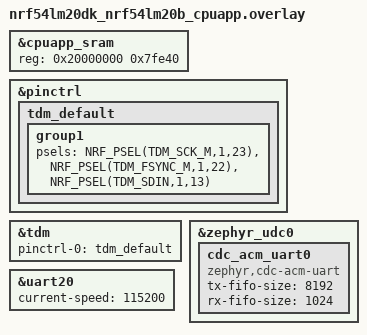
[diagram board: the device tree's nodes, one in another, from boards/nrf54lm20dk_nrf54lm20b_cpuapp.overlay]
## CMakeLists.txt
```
cmake_minimum_required(VERSION 3.20.0)

find_package(Zephyr REQUIRED HINTS $ENV{ZEPHYR_BASE})
project(16_3mic_eval)

target_sources(app PRIVATE
  src/main.c
  src/eval_config.c
  src/audio_capture_adapter.c
  src/beamformer_delay_sum.c
  src/telemetry_protocol.c
  src/telemetry_transport.c
  src/run_controller.c
  src/command_interface.c
)

target_include_directories(app PRIVATE src)
```

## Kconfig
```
#
# 3-microphone beamforming evaluation firmware
#

source "Kconfig.zephyr"

menu "3-mic TDM capture"

config EVAL_TDM_SLOTS
	int "TDM slots per frame"
	range 4 8
	default 4
	help
	  Number of 32-bit slots in each TDM frame. Three mics plus one unused
	  slot by default, giving SCK = 16 kHz * 32 * 4 = 2.048 MHz. Raise to 8
	  if the mic needs a longer frame or a faster SCK.

config EVAL_SLOT_LEFT
	int "TDM slot of the left mic"
	range 0 7
	default 0
	help
	  Slot order follows the WS -> WSO daisy chain. The mic whose WS is
	  driven by the nRF FSYNC pin is slot 0.

config EVAL_SLOT_CENTER
	int "TDM slot of the center mic"
	range 0 7
	default 1

config EVAL_SLOT_RIGHT
	int "TDM slot of the right mic"
	range 0 7
	default 2

config EVAL_SLOT_BIT_OFFSET
	int "Bit offset of the sample inside its TDM slot"
	range 0 1
	default 0
	help
	  The nRF TDM driver samples PCM_SHORT frames with no channel delay. If
	  a logic analyzer shows the mic starting its MSB one SCK after the
	  frame-sync edge, set this to 1.

config EVAL_CAPTURE_GAIN_SHIFT
	int "Extra digital gain from the mic's 24-bit domain, 6 dB per step"
	range 0 4
	default 0

config EVAL_FRAME_QUEUE_DEPTH
	int "Frames buffered between the capture thread and the evaluation thread"
	range 2 32
	default 8
	help
	  Each entry is one 16 ms three-channel frame (1.5 KB). If the
	  evaluation thread falls behind, capture never blocks: the frame is
	  dropped and counted.

endmenu

menu "Beamformer and run defaults"

config EVAL_DEFAULT_DURATION_S
	int "Default run duration (s), 0 = until 'stop'"
	default 20

config EVAL_MAX_DELAY_SAMPLES
	int "Longest beamformer delay supported, in samples"
	range 1 127
	default 64
	help
	  At 16 kHz one sample is 62.5 us, or about 2.1 cm of path length.

config EVAL_BF_LEFT_DELAY
	int "Default left-mic delay (samples)"
	default 0

config EVAL_BF_CENTER_DELAY
	int "Default center-mic delay (samples)"
	default 0

config EVAL_BF_RIGHT_DELAY
	int "Default right-mic delay (samples)"
	default 0

config EVAL_BF_GAIN_Q15
	int "Default per-mic beamformer weight, Q15 (32767 = 1.0)"
	range 0 32767
	default 32767

config EVAL_TX_RING_BYTES
	int "Telemetry transmit ring buffer (bytes)"
	default 65536
	help
	  Audio and telemetry packets are staged here and drained into the USB
	  CDC ACM FIFO. Four 16-bit streams are 128 kB/s, so 64 KiB is about
	  half a second of slack. When full, audio chunks are dropped and the
	  host records a gap.

config EVAL_STATUS_PERIOD_MS
	int "AUDIO_STATS emission period during a run (ms)"
	default 1000

config EVAL_TEXT_MODE_AT_BOOT
	bool "Start in human-readable text mode (binary framing enabled by the host tool)"
	default y

endmenu
```

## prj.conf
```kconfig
# --- Audio capture (TDM, three ICS-52000 microphones) ---
CONFIG_I2S=y

# --- Telemetry link: USB high-speed, CDC ACM. The stack initialises and
#     enables itself at boot; the class exposes the interrupt-driven UART API
#     that telemetry_transport.c drains its ring through. ---
CONFIG_USB_DEVICE_STACK_NEXT=y
CONFIG_USBD_CDC_ACM_CLASS=y
CONFIG_CDC_ACM_SERIAL_INITIALIZE_AT_BOOT=y
CONFIG_CDC_ACM_SERIAL_MANUFACTURER_STRING="iLAB"
CONFIG_CDC_ACM_SERIAL_PRODUCT_STRING="3-mic beamforming eval"
CONFIG_SERIAL=y
CONFIG_UART_INTERRUPT_DRIVEN=y
CONFIG_UART_LINE_CTRL=y
CONFIG_USBD_LOG_LEVEL_ERR=y
CONFIG_UDC_DRIVER_LOG_LEVEL_ERR=y
CONFIG_USBD_CDC_ACM_LOG_LEVEL_OFF=y

# --- Debug console and Zephyr logs stay on uart20 (J-Link VCOM, 115200) ---
CONFIG_CONSOLE=y
CONFIG_UART_CONSOLE=y
CONFIG_LOG=y
CONFIG_LOG_MODE_DEFERRED=y
CONFIG_LOG_PROCESS_THREAD=y
CONFIG_LOG_BUFFER_SIZE=4096
CONFIG_LOG_DEFAULT_LEVEL=3

# --- Threads ---
CONFIG_MAIN_STACK_SIZE=4096
CONFIG_SYSTEM_WORKQUEUE_STACK_SIZE=2048
CONFIG_HEAP_MEM_POOL_SIZE=0
CONFIG_THREAD_NAME=y
CONFIG_THREAD_STACK_INFO=y

# --- Buttons / LEDs (BTN1 start, BTN2 stop, LED1 run, LED2 host connected) ---
CONFIG_GPIO=y
CONFIG_DK_LIBRARY=y

# ring buffers larger than 32 KiB need this
CONFIG_RING_BUFFER=y
CONFIG_RING_BUFFER_LARGE=y

# --- Evaluation defaults ---
CONFIG_EVAL_DEFAULT_DURATION_S=20
```

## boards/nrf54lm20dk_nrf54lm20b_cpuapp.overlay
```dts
/*
 * nRF54LM20 DK, 3-mic beamforming evaluation.
 *
 * 3x ICS-52000 TDM daisy chain (left / center / right):
 *   all SCK      -> P1.23  (TDM_SCK_M)
 *   all SD       -> P1.13  (TDM_SDIN), plus ~100k pulldown to GND
 *   nRF P1.22    -> WS  of left mic   (TDM_FSYNC_M, slot 0)
 *   left   WSO   -> WS  of center mic (slot 1)
 *   center WSO   -> WS  of right mic  (slot 2)
 *   right  WSO   -> not connected
 *   VDD -> 3V3, GND -> GND
 *
 * Links to the laptop (two cables):
 *   "nRF USB" USB-C port -> USB CDC ACM, audio + telemetry (this file, cdc_acm_uart0)
 *   "IMCU" USB port      -> J-Link: flashing, and uart20 debug console at 115200
 */

#include <dt-bindings/pinctrl/nrf-pinctrl.h>

&cpuapp_sram {
	reg = <0x20000000 0x7fe40>;
	ranges = <0x0 0x20000000 0x7fe40>;
};

&pinctrl {
	tdm_default: tdm_default {
		group1 {
			psels = <NRF_PSEL(TDM_SCK_M,1,23)>,
				<NRF_PSEL(TDM_FSYNC_M,1,22)>,
				<NRF_PSEL(TDM_SDIN,1,13)>;
		};
	};
};

&tdm {
	status = "okay";
	pinctrl-0 = <&tdm_default>;
	pinctrl-names = "default";
};

&zephyr_udc0 {
	cdc_acm_uart0: cdc_acm_uart0 {
		compatible = "zephyr,cdc-acm-uart";
		/* Large FIFOs: four 512-byte audio packets per 16 ms frame. */
		tx-fifo-size = <8192>;
		rx-fifo-size = <1024>;
	};
};

&uart20 {
	current-speed = <115200>;
};
```

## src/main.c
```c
/*
 * 3-microphone beamforming evaluation firmware for the nRF54LM20 DK.
 *
 * Threads, highest priority first:
 *   audio_capture (6)  TDM DMA -> int16 L/C/R frames -> frame queue, never blocks
 *   eval          (7)  on-device delay-and-sum, level stats, audio streams to the host
 *   telemetry_rx  (8)  commands from the host
 *   main               10 ms housekeeping
 *
 * BTN1 starts a run with the current configuration, BTN2 stops it. Everything
 * else is driven over the USB link (see command_interface.c and README).
 * Zephyr logs go to uart20 (J-Link VCOM); audio and telemetry go to USB CDC ACM.
 */
#include <zephyr/kernel.h>
#include <zephyr/logging/log.h>
#include <dk_buttons_and_leds.h>

#include "audio_capture_adapter.h"
#include "command_interface.h"
#include "run_controller.h"
#include "telemetry_transport.h"

LOG_MODULE_REGISTER(main, LOG_LEVEL_INF);

static void button_changed(uint32_t state, uint32_t changed)
{
	uint32_t pressed = state & changed;

	if (pressed & DK_BTN1_MSK) {
		char err[120];

		if (run_controller_start(err, sizeof(err)) == 0) {
			LOG_INF("BTN1: start queued");
			tt_send_text(TP_TEXT, "BTN1: start");
		} else {
			LOG_WRN("BTN1: start refused: %s", err);
		}
	}
	if (pressed & DK_BTN2_MSK) {
		if (run_controller_stop("button") == 0) {
			LOG_INF("BTN2: stop queued");
		} else {
			LOG_WRN("BTN2: nothing to stop");
		}
	}
}

int main(void)
{
	int err;

	err = dk_leds_init();
	if (err) {
		return err;
	}
	err = dk_buttons_init(button_changed);
	if (err) {
		return err;
	}

	err = tt_init();
	if (err) {
		LOG_ERR("telemetry init failed: %d", err);
		for (;;) {
			dk_set_led_on(DK_LED1);
			dk_set_led_on(DK_LED2);
			k_sleep(K_MSEC(100));
			dk_set_led_off(DK_LED1);
			dk_set_led_off(DK_LED2);
			k_sleep(K_MSEC(100));
		}
	}
	command_interface_init();

	tt_send_text(TP_TEXT, "");
	tt_send_text(TP_TEXT, "=== 3-mic beamforming evaluation (16_3mic_eval) ===");
	tt_send_text(TP_TEXT, "type 'help' for commands, 'binary_mode on' for the host tool");

	err = audio_capture_init();
	if (err) {
		LOG_ERR("capture init failed: %d", err);
		tt_send_text(TP_ERROR, "err: capture init failed (%d)", err);
		return err;
	}

	err = run_controller_init();
	if (err) {
		return err;
	}

	err = audio_capture_start();
	if (err) {
		LOG_ERR("capture start failed: %d", err);
		return err;
	}

	LOG_INF("ready: %u Hz, %u mics, %u-sample frames; BTN1 start, BTN2 stop",
		audio_capture_sample_rate_hz(), audio_capture_channels(),
		(unsigned)EVAL_FRAME_SAMPLES);
	tt_send_text(TP_TEXT, "ready: %u Hz, %u mics, %u-sample frames; BTN1 start, BTN2 stop",
		     audio_capture_sample_rate_hz(), audio_capture_channels(),
		     (unsigned)EVAL_FRAME_SAMPLES);

	for (;;) {
		run_controller_tick();
		k_sleep(K_MSEC(10));
	}
}
```

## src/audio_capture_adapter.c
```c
#include <errno.h>
#include <string.h>

#include <zephyr/device.h>
#include <zephyr/devicetree.h>
#include <zephyr/drivers/i2s.h>
#include <zephyr/kernel.h>
#include <zephyr/logging/log.h>
#include <zephyr/sys/atomic.h>
#include <zephyr/sys/util.h>

#include "audio_capture_adapter.h"

LOG_MODULE_REGISTER(capture, LOG_LEVEL_INF);

/*
 * Capture format, the same as 15_3micBF: each ICS-52000 emits a 24-bit sample
 * left-justified in a 32-bit TDM slot. The frame holds CONFIG_EVAL_TDM_SLOTS
 * slots (3 mics + 1 unused by default), SCK = 16000 * 32 * 4 = 2.048 MHz.
 */
#define SAMPLE_RATE       EVAL_SAMPLE_RATE_HZ
#define SAMPLE_BIT_WIDTH  32
#define CHANNELS          CONFIG_EVAL_TDM_SLOTS
#define BLOCK_FRAMES      EVAL_FRAME_SAMPLES
#define BLOCK_BYTES       (BLOCK_FRAMES * CHANNELS * sizeof(int32_t))
#define BLOCK_COUNT       4

#define SLOT_LEFT         CONFIG_EVAL_SLOT_LEFT
#define SLOT_CENTER       CONFIG_EVAL_SLOT_CENTER
#define SLOT_RIGHT        CONFIG_EVAL_SLOT_RIGHT

#define TDM_NODE DT_NODELABEL(tdm)

#if !DT_NODE_HAS_STATUS(TDM_NODE, okay)
#error "TDM node is not enabled in the devicetree"
#endif

BUILD_ASSERT(SLOT_LEFT < CHANNELS && SLOT_CENTER < CHANNELS && SLOT_RIGHT < CHANNELS,
	     "Mic slot index must be below CONFIG_EVAL_TDM_SLOTS");
BUILD_ASSERT(SLOT_LEFT != SLOT_CENTER && SLOT_LEFT != SLOT_RIGHT && SLOT_CENTER != SLOT_RIGHT,
	     "Each mic needs its own TDM slot");

K_MEM_SLAB_DEFINE_IN_SECT_STATIC(rx_slab, __nocache, BLOCK_BYTES, BLOCK_COUNT, 4);
K_THREAD_STACK_DEFINE(capture_stack, 4096);
K_MSGQ_DEFINE(frame_queue, sizeof(struct capture_frame), CONFIG_EVAL_FRAME_QUEUE_DEPTH, 4);

static const struct device *const i2s = DEVICE_DT_GET(TDM_NODE);

static const struct i2s_config i2s_cfg = {
	.word_size = SAMPLE_BIT_WIDTH,
	.channels = CHANNELS,
	/*
	 * TDM with a one-SCK frame-sync pulse: the nRF TDM driver only allows
	 * more than two channels in the PCM formats.
	 */
	.format = I2S_FMT_DATA_FORMAT_PCM_SHORT,
	.options = I2S_OPT_BIT_CLK_MASTER | I2S_OPT_FRAME_CLK_MASTER,
	.frame_clk_freq = SAMPLE_RATE,
	.mem_slab = &rx_slab,
	.block_size = BLOCK_BYTES,
	.timeout = 2000,
};

/* eval_mic_t order: left, center, right. */
static const uint8_t mic_slot[EVAL_MIC_COUNT] = { SLOT_LEFT, SLOT_CENTER, SLOT_RIGHT };

static struct k_thread capture_thread_data;
static atomic_t capture_active = ATOMIC_INIT(0);
static struct audio_capture_stats stats;
static struct k_spinlock stats_lock;

/* The one frame being assembled; copied into the queue by value. */
static struct capture_frame work_frame;

static inline int16_t unpack(int32_t raw)
{
	/*
	 * 32-bit slot -> 24-bit sample -> 16-bit with optional gain, saturated.
	 * CONFIG_EVAL_SLOT_BIT_OFFSET compensates for a mic that launches its
	 * MSB one SCK after the frame-sync edge.
	 */
	int32_t s24 = (int32_t)((uint32_t)raw << CONFIG_EVAL_SLOT_BIT_OFFSET) >> 8;
	int32_t s = s24 >> (8 - CONFIG_EVAL_CAPTURE_GAIN_SHIFT);

	if (s > INT16_MAX) {
		return INT16_MAX;
	}
	if (s < INT16_MIN) {
		return INT16_MIN;
	}
	return (int16_t)s;
}

static void capture(void *a, void *b, void *c)
{
	ARG_UNUSED(a);
	ARG_UNUSED(b);
	ARG_UNUSED(c);

	int err = i2s_trigger(i2s, I2S_DIR_RX, I2S_TRIGGER_START);

	if (err) {
		LOG_ERR("I2S start failed: %d", err);
		atomic_clear(&capture_active);
		return;
	}

	LOG_INF("capture: %u Hz, %u mics in %d TDM slots, %d-bit slots, %u samples/frame (%u ms), queue %d",
		(unsigned)SAMPLE_RATE, (unsigned)EVAL_MIC_COUNT, CHANNELS, SAMPLE_BIT_WIDTH,
		(unsigned)BLOCK_FRAMES, (unsigned)EVAL_FRAME_MS, CONFIG_EVAL_FRAME_QUEUE_DEPTH);
	LOG_INF("slots L/C/R = %d/%d/%d, bit offset %d", SLOT_LEFT, SLOT_CENTER, SLOT_RIGHT,
		CONFIG_EVAL_SLOT_BIT_OFFSET);

	while (atomic_get(&capture_active)) {
		void *block;
		size_t bytes;

		err = i2s_read(i2s, &block, &bytes);
		if (err) {
			if (err != -EAGAIN) {
				k_spinlock_key_t key = k_spin_lock(&stats_lock);

				stats.i2s_errors++;
				k_spin_unlock(&stats_lock, key);
				LOG_WRN("I2S read failed: %d", err);
			}
			continue;
		}

		uint32_t t0 = k_cycle_get_32();
		const int32_t *tdm = block;
		size_t frames = MIN(bytes / (CHANNELS * sizeof(int32_t)), (size_t)BLOCK_FRAMES);

		for (size_t i = 0; i < frames; i++) {
			for (size_t m = 0; m < EVAL_MIC_COUNT; m++) {
				work_frame.mic[m][i] = unpack(tdm[CHANNELS * i + mic_slot[m]]);
			}
		}
		k_mem_slab_free(&rx_slab, block);

		work_frame.count = (uint16_t)frames;

		uint32_t us = k_cyc_to_us_floor32(k_cycle_get_32() - t0);
		k_spinlock_key_t key = k_spin_lock(&stats_lock);

		/* seq advances even when the frame is dropped, so the host sees the hole. */
		work_frame.seq = stats.frames_captured++;
		stats.unpack_us_last = us;
		if (us > stats.unpack_us_max) {
			stats.unpack_us_max = us;
		}

		uint32_t used = k_msgq_num_used_get(&frame_queue);

		if (used > stats.queue_high_water) {
			stats.queue_high_water = used;
		}
		if (k_msgq_put(&frame_queue, &work_frame, K_NO_WAIT) != 0) {
			stats.frames_dropped++;
		}
		k_spin_unlock(&stats_lock, key);
	}

	i2s_trigger(i2s, I2S_DIR_RX, I2S_TRIGGER_DROP);
}

int audio_capture_init(void)
{
	if (!device_is_ready(i2s)) {
		return -ENODEV;
	}
	memset(&stats, 0, sizeof(stats));
	stats.queue_depth = CONFIG_EVAL_FRAME_QUEUE_DEPTH;
	return i2s_configure(i2s, I2S_DIR_RX, &i2s_cfg);
}

int audio_capture_start(void)
{
	if (!atomic_cas(&capture_active, 0, 1)) {
		return -EALREADY;
	}
	k_thread_create(&capture_thread_data, capture_stack, K_THREAD_STACK_SIZEOF(capture_stack),
			capture, NULL, NULL, NULL, 6, 0, K_NO_WAIT);
	k_thread_name_set(&capture_thread_data, "audio_capture");
	return 0;
}

struct k_msgq *audio_capture_queue(void)
{
	return &frame_queue;
}

void audio_capture_get_stats(struct audio_capture_stats *out)
{
	k_spinlock_key_t key = k_spin_lock(&stats_lock);

	*out = stats;
	k_spin_unlock(&stats_lock, key);
}

void audio_capture_reset_stats(void)
{
	k_spinlock_key_t key = k_spin_lock(&stats_lock);
	uint32_t captured = stats.frames_captured;

	memset(&stats, 0, sizeof(stats));
	stats.frames_captured = captured;   /* keep the running frame counter monotonic */
	stats.queue_depth = CONFIG_EVAL_FRAME_QUEUE_DEPTH;
	k_spin_unlock(&stats_lock, key);
}

uint32_t audio_capture_sample_rate_hz(void)
{
	return SAMPLE_RATE;
}

uint8_t audio_capture_channels(void)
{
	return EVAL_MIC_COUNT;
}

uint8_t audio_capture_tdm_slots(void)
{
	return CHANNELS;
}
```

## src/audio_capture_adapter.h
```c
/*
 * Microphone capture: three ICS-52000 microphones daisy-chained on one TDM
 * bus, delivered to the evaluation thread as synchronized frames through a
 * message queue. Capture never blocks on the consumer; if the queue is full
 * the frame is dropped and counted (the host sees the hole in the sample
 * index and records a gap).
 *
 * Channel map (boards/nrf54lm20dk_nrf54lm20b_cpuapp.overlay):
 *
 *   TDM slot 0 -> LEFT    WS driven by the nRF FSYNC pin
 *   TDM slot 1 -> CENTER  WS driven by the left mic's WSO
 *   TDM slot 2 -> RIGHT   WS driven by the center mic's WSO
 *   slot 3     -> unused, reads 0 through the SD pulldown
 *   pins: SCK P1.23, FSYNC P1.22, SD P1.13
 *
 * All three share SCK and one frame-sync pulse, so they are sampled on the
 * same clock edge: the array is synchronized by construction.
 */
#ifndef AUDIO_CAPTURE_ADAPTER_H_
#define AUDIO_CAPTURE_ADAPTER_H_

#include <stdbool.h>
#include <stdint.h>
#include <zephyr/kernel.h>

#include "eval_config.h"

struct capture_frame {
	uint32_t seq;            /* capture counter; holes mean dropped frames */
	uint16_t count;          /* samples per channel                        */
	int16_t mic[EVAL_MIC_COUNT][EVAL_FRAME_SAMPLES];
};

struct audio_capture_stats {
	uint32_t frames_captured;
	uint32_t frames_dropped;     /* queue full */
	uint32_t queue_high_water;
	uint32_t queue_depth;
	uint32_t i2s_errors;
	uint32_t unpack_us_last;
	uint32_t unpack_us_max;
};

int audio_capture_init(void);
int audio_capture_start(void);

struct k_msgq *audio_capture_queue(void);

void audio_capture_get_stats(struct audio_capture_stats *out);
void audio_capture_reset_stats(void);

uint32_t audio_capture_sample_rate_hz(void);
uint8_t audio_capture_channels(void);
uint8_t audio_capture_tdm_slots(void);

#endif /* AUDIO_CAPTURE_ADAPTER_H_ */
```

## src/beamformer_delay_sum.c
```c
#include <string.h>

#include "beamformer_delay_sum.h"

#if EVAL_MAX_DELAY_SAMPLES >= BF_HISTORY_LEN
#error "BF_HISTORY_LEN must exceed EVAL_MAX_DELAY_SAMPLES"
#endif

static inline int16_t sat16(int32_t x, uint32_t *clips)
{
	if (x > INT16_MAX) {
		(*clips)++;
		return INT16_MAX;
	}
	if (x < INT16_MIN) {
		(*clips)++;
		return INT16_MIN;
	}
	return (int16_t)x;
}

void bf_init(struct bf_delay_sum *bf, const eval_bf_config_t *cfg)
{
	memset(bf, 0, sizeof(*bf));
	bf->cfg = *cfg;
	for (int m = 0; m < (int)EVAL_MIC_COUNT; m++) {
		if (bf->cfg.delay_samples[m] < 0) {
			bf->cfg.delay_samples[m] = 0;
		}
		if (bf->cfg.delay_samples[m] > EVAL_MAX_DELAY_SAMPLES) {
			bf->cfg.delay_samples[m] = EVAL_MAX_DELAY_SAMPLES;
		}
	}
}

void bf_reset(struct bf_delay_sum *bf)
{
	memset(bf->history, 0, sizeof(bf->history));
	bf->pos = 0;
	bf->clips = 0;
}

void bf_process(struct bf_delay_sum *bf, const int16_t *const mic[EVAL_MIC_COUNT],
		int16_t *out, size_t count)
{
	for (size_t i = 0; i < count; i++) {
		int64_t acc = 0;

		for (int m = 0; m < (int)EVAL_MIC_COUNT; m++) {
			bf->history[m][bf->pos] = mic[m][i];

			int32_t tap = bf->history[m][(bf->pos - (uint32_t)bf->cfg.delay_samples[m]) &
						     BF_HISTORY_MASK];

			/* gain is Q15: x * g >> 15 */
			acc += ((int64_t)tap * bf->cfg.gain_q15[m]) >> 15;
		}
		bf->pos = (bf->pos + 1U) & BF_HISTORY_MASK;

		/* Average of the three weighted taps, then output gain, truncating toward zero. */
		int32_t avg = (int32_t)(acc / (int64_t)EVAL_MIC_COUNT);
		int32_t y = (int32_t)(((int64_t)avg * bf->cfg.out_gain_q15) >> 15);

		out[i] = sat16(y, &bf->clips);
	}
}
```

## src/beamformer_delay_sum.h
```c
/*
 * Three-microphone delay-and-sum beamformer, integer arithmetic only.
 *
 *   y[n] = out_gain * sum_m( gain[m] * x_m[n - delay[m]] ) / 3
 *
 * Pure C with no Zephyr dependency. tools/dsp_paths.py reproduces the exact
 * same arithmetic so the host can rebuild the device's output bit for bit
 * from the raw microphone recordings, and compute any other delay set
 * offline from the same audio.
 */
#ifndef BEAMFORMER_DELAY_SUM_H_
#define BEAMFORMER_DELAY_SUM_H_

#include <stddef.h>
#include <stdint.h>

#include "eval_config.h"

#ifdef __cplusplus
extern "C" {
#endif

/* Power of two, larger than EVAL_MAX_DELAY_SAMPLES. */
#define BF_HISTORY_LEN   128
#define BF_HISTORY_MASK  (BF_HISTORY_LEN - 1)

struct bf_delay_sum {
	eval_bf_config_t cfg;
	int16_t history[EVAL_MIC_COUNT][BF_HISTORY_LEN];
	uint32_t pos;
	uint32_t clips;
};

void bf_init(struct bf_delay_sum *bf, const eval_bf_config_t *cfg);
void bf_reset(struct bf_delay_sum *bf);

/* Processes `count` samples from each mic into `out`. */
void bf_process(struct bf_delay_sum *bf, const int16_t *const mic[EVAL_MIC_COUNT],
		int16_t *out, size_t count);

#ifdef __cplusplus
}
#endif

#endif /* BEAMFORMER_DELAY_SUM_H_ */
```

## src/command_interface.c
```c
#include <ctype.h>
#include <stdio.h>
#include <stdlib.h>
#include <string.h>

#include <zephyr/kernel.h>
#include <zephyr/logging/log.h>

#include "command_interface.h"
#include "eval_config.h"
#include "run_controller.h"
#include "telemetry_transport.h"

LOG_MODULE_REGISTER(cmd, LOG_LEVEL_INF);

#define MAX_ARGS 6

static const char *const help_lines[] = {
	"commands:",
	"  help | hello | status | config | reset",
	"  start | stop                       run with the current settings (BTN1 / BTN2 do the same)",
	"  set_duration <s>                   0 = until stop",
	"  set_angle <deg> | set_distance <cm> | set_label <text> | set_env <text> | set_clip <text>",
	"  set_delay <left> <center> <right>  beamformer delays in samples (62.5 us each)",
	"  set_gain <left> <center> <right>   per-mic Q15 weights, 32767 = 1.0",
	"  set_out_gain <q15>                 beamformer output gain",
	"  set_stream <left|center|right|bf> <on|off>",
	"  levels [on|off]                    print mic levels once, every second, or stop",
	"  binary_mode <on|off>               framed packets for the host tool",
};

static void ack(const char *fmt, ...)
{
	char msg[200];
	va_list ap;

	va_start(ap, fmt);
	vsnprintf(msg, sizeof(msg), fmt, ap);
	va_end(ap);
	tt_send_text(TP_ACK, "ok: %s", msg);
}

static void fail(const char *fmt, ...)
{
	char msg[200];
	va_list ap;

	va_start(ap, fmt);
	vsnprintf(msg, sizeof(msg), fmt, ap);
	va_end(ap);
	tt_send_text(TP_ERROR, "err: %s", msg);
}

static bool parse_int(const char *s, long min, long max, long *out)
{
	char *end;
	long v = strtol(s, &end, 10);

	if (end == s || *end != '\0' || v < min || v > max) {
		return false;
	}
	*out = v;
	return true;
}

static bool parse_on_off(const char *s, bool *out)
{
	if (strcmp(s, "on") == 0 || strcmp(s, "1") == 0) {
		*out = true;
		return true;
	}
	if (strcmp(s, "off") == 0 || strcmp(s, "0") == 0) {
		*out = false;
		return true;
	}
	return false;
}

static bool require_idle(void)
{
	if (!run_controller_config_mutable()) {
		fail("stop the run first");
		return false;
	}
	return true;
}

static void copy_text(char *dst, size_t cap, const char *src)
{
	size_t n = strlen(src);

	if (n >= cap) {
		n = cap - 1;
	}
	memcpy(dst, src, n);
	dst[n] = '\0';
	/* Keep JSON payloads valid. */
	for (size_t i = 0; i < n; i++) {
		if (dst[i] == '"' || dst[i] == '\\') {
			dst[i] = '_';
		}
	}
}

static void handle(int argc, char *argv[], const char *rest_after_cmd)
{
	const char *cmd = argv[0];
	eval_run_config_t *cfg = run_controller_config();

	if (strcmp(cmd, "help") == 0) {
		for (size_t i = 0; i < ARRAY_SIZE(help_lines); i++) {
			tt_send_text(TP_TEXT, "%s", help_lines[i]);
		}
		ack("help");
	} else if (strcmp(cmd, "hello") == 0) {
		run_controller_emit_hello();
		ack("hello");
	} else if (strcmp(cmd, "status") == 0) {
		run_controller_emit_status();
		ack("status");
	} else if (strcmp(cmd, "config") == 0) {
		run_controller_emit_config();
		ack("config");
	} else if (strcmp(cmd, "reset") == 0) {
		if (!require_idle()) {
			return;
		}
		run_controller_reset();
		ack("reset");
	} else if (strcmp(cmd, "start") == 0) {
		char err[120];

		if (run_controller_start(err, sizeof(err)) == 0) {
			ack("start");
		} else {
			fail("%s", err);
		}
	} else if (strcmp(cmd, "stop") == 0) {
		if (run_controller_stop("command") == 0) {
			ack("stop");
		} else {
			fail("nothing to stop");
		}
	} else if (strcmp(cmd, "set_duration") == 0) {
		long v;

		if (argc != 2 || !parse_int(argv[1], 0, 3600, &v)) {
			fail("usage: set_duration <0..3600>");
			return;
		}
		if (!require_idle()) {
			return;
		}
		cfg->duration_s = (uint16_t)v;
		ack("duration %u s", cfg->duration_s);
	} else if (strcmp(cmd, "set_angle") == 0) {
		long v;

		if (argc != 2 || !parse_int(argv[1], -180, 180, &v)) {
			fail("usage: set_angle <-180..180>");
			return;
		}
		if (!require_idle()) {
			return;
		}
		cfg->angle_deg = (int16_t)v;
		ack("angle %d", cfg->angle_deg);
	} else if (strcmp(cmd, "set_distance") == 0) {
		long v;

		if (argc != 2 || !parse_int(argv[1], 0, 10000, &v)) {
			fail("usage: set_distance <cm>");
			return;
		}
		if (!require_idle()) {
			return;
		}
		cfg->distance_cm = (uint16_t)v;
		ack("distance %u cm", cfg->distance_cm);
	} else if (strcmp(cmd, "set_label") == 0 || strcmp(cmd, "set_env") == 0 ||
		   strcmp(cmd, "set_clip") == 0) {
		if (argc < 2) {
			fail("usage: %s <text>", cmd);
			return;
		}
		if (!require_idle()) {
			return;
		}
		if (cmd[4] == 'l') {
			copy_text(cfg->label, sizeof(cfg->label), rest_after_cmd);
			ack("label %s", cfg->label);
		} else if (cmd[4] == 'e') {
			copy_text(cfg->environment, sizeof(cfg->environment), rest_after_cmd);
			ack("env %s", cfg->environment);
		} else {
			copy_text(cfg->clip, sizeof(cfg->clip), rest_after_cmd);
			ack("clip %s", cfg->clip);
		}
	} else if (strcmp(cmd, "set_delay") == 0) {
		long d[EVAL_MIC_COUNT];

		if (argc != 4 || !parse_int(argv[1], 0, EVAL_MAX_DELAY_SAMPLES, &d[0]) ||
		    !parse_int(argv[2], 0, EVAL_MAX_DELAY_SAMPLES, &d[1]) ||
		    !parse_int(argv[3], 0, EVAL_MAX_DELAY_SAMPLES, &d[2])) {
			fail("usage: set_delay <left> <center> <right>  (0..%d samples)",
			     EVAL_MAX_DELAY_SAMPLES);
			return;
		}
		if (!require_idle()) {
			return;
		}
		for (int m = 0; m < (int)EVAL_MIC_COUNT; m++) {
			cfg->bf.delay_samples[m] = (int16_t)d[m];
		}
		ack("delay left %ld center %ld right %ld", d[0], d[1], d[2]);
	} else if (strcmp(cmd, "set_gain") == 0) {
		long g[EVAL_MIC_COUNT];

		if (argc != 4 || !parse_int(argv[1], 0, 32767, &g[0]) ||
		    !parse_int(argv[2], 0, 32767, &g[1]) || !parse_int(argv[3], 0, 32767, &g[2])) {
			fail("usage: set_gain <left> <center> <right>  (0..32767)");
			return;
		}
		if (!require_idle()) {
			return;
		}
		for (int m = 0; m < (int)EVAL_MIC_COUNT; m++) {
			cfg->bf.gain_q15[m] = (int16_t)g[m];
		}
		ack("gain left %ld center %ld right %ld", g[0], g[1], g[2]);
	} else if (strcmp(cmd, "set_out_gain") == 0) {
		long v;

		if (argc != 2 || !parse_int(argv[1], 0, 32767, &v)) {
			fail("usage: set_out_gain <0..32767>");
			return;
		}
		if (!require_idle()) {
			return;
		}
		cfg->bf.out_gain_q15 = (int16_t)v;
		ack("out_gain %ld", v);
	} else if (strcmp(cmd, "set_stream") == 0) {
		bool on;

		if (argc != 3 || !parse_on_off(argv[2], &on)) {
			fail("usage: set_stream <left|center|right|bf> <on|off>");
			return;
		}
		if (!require_idle()) {
			return;
		}
		if (strcmp(argv[1], "bf") == 0) {
			cfg->stream_bf = on;
		} else {
			int m = eval_mic_from_name(argv[1]);

			if (m < 0) {
				fail("unknown stream %s", argv[1]);
				return;
			}
			cfg->stream_raw[m] = on;
		}
		ack("stream %s %s", argv[1], on ? "on" : "off");
	} else if (strcmp(cmd, "levels") == 0) {
		if (argc == 1) {
			run_controller_request_levels(false, false);
			ack("levels once");
		} else if (strcmp(argv[1], "on") == 0) {
			run_controller_request_levels(true, false);
			ack("levels on");
		} else if (strcmp(argv[1], "off") == 0) {
			run_controller_request_levels(false, true);
			ack("levels off");
		} else {
			fail("usage: levels [on|off]");
		}
	} else if (strcmp(cmd, "binary_mode") == 0) {
		bool on;

		if (argc != 2 || !parse_on_off(argv[1], &on)) {
			fail("usage: binary_mode <on|off>");
			return;
		}
		/* Answer in the mode the host asked for, so the ack is parseable either way. */
		tt_set_binary_mode(on);
		ack("binary_mode %s", on ? "on" : "off");
	} else {
		fail("unknown command '%s' (try help)", cmd);
	}
}

void command_interface_handle_line(const char *line)
{
	char buf[256];
	char *argv[MAX_ARGS];
	int argc = 0;

	strncpy(buf, line, sizeof(buf) - 1);
	buf[sizeof(buf) - 1] = '\0';

	/* Trim. */
	char *s = buf;

	while (*s && isspace((unsigned char)*s)) {
		s++;
	}
	size_t n = strlen(s);

	while (n > 0 && isspace((unsigned char)s[n - 1])) {
		s[--n] = '\0';
	}
	if (n == 0) {
		return;
	}

	/* Remember the text after the command word for free-text setters. */
	char rest[256];

	strcpy(rest, s);
	char *sp = strchr(rest, ' ');
	const char *rest_after_cmd = "";

	if (sp) {
		sp++;
		while (*sp == ' ') {
			sp++;
		}
		rest_after_cmd = sp;
	}

	char *tok = strtok(s, " \t");

	while (tok && argc < MAX_ARGS) {
		argv[argc++] = tok;
		tok = strtok(NULL, " \t");
	}
	if (argc == 0) {
		return;
	}
	handle(argc, argv, rest_after_cmd);
}

void command_interface_init(void)
{
	tt_set_rx_callbacks(command_interface_handle_line, NULL);
}
```

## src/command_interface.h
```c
/*
 * Text command interface. One command per line, from a terminal or framed in
 * a TP_COMMAND packet by the host tool. Every command is answered with an
 * "ok: ..." or "err: ..." line (TP_ACK / TP_ERROR in binary mode).
 */
#ifndef COMMAND_INTERFACE_H_
#define COMMAND_INTERFACE_H_

void command_interface_init(void);
void command_interface_handle_line(const char *line);

#endif /* COMMAND_INTERFACE_H_ */
```

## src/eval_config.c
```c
#include <string.h>

#include "eval_config.h"

#ifndef CONFIG_EVAL_DEFAULT_DURATION_S
#define CONFIG_EVAL_DEFAULT_DURATION_S 20
#endif
#ifndef CONFIG_EVAL_BF_LEFT_DELAY
#define CONFIG_EVAL_BF_LEFT_DELAY 0
#endif
#ifndef CONFIG_EVAL_BF_CENTER_DELAY
#define CONFIG_EVAL_BF_CENTER_DELAY 0
#endif
#ifndef CONFIG_EVAL_BF_RIGHT_DELAY
#define CONFIG_EVAL_BF_RIGHT_DELAY 0
#endif
#ifndef CONFIG_EVAL_BF_GAIN_Q15
#define CONFIG_EVAL_BF_GAIN_Q15 32767
#endif

static const char *const mic_names[EVAL_MIC_COUNT] = { "left", "center", "right" };

const char *eval_mic_name(eval_mic_t m)
{
	return ((unsigned)m < EVAL_MIC_COUNT) ? mic_names[m] : "?";
}

const char *eval_stream_name(uint16_t stream_id)
{
	switch (stream_id) {
	case EVAL_STREAM_RAW_LEFT: return "raw_left";
	case EVAL_STREAM_RAW_CENTER: return "raw_center";
	case EVAL_STREAM_RAW_RIGHT: return "raw_right";
	case EVAL_STREAM_BF: return "bf";
	default: return "?";
	}
}

int eval_mic_from_name(const char *name)
{
	for (int i = 0; i < (int)EVAL_MIC_COUNT; i++) {
		if (strcmp(name, mic_names[i]) == 0) {
			return i;
		}
	}
	/* Accept the single-letter forms too. */
	if (strcmp(name, "l") == 0) {
		return EVAL_MIC_LEFT;
	}
	if (strcmp(name, "c") == 0) {
		return EVAL_MIC_CENTER;
	}
	if (strcmp(name, "r") == 0) {
		return EVAL_MIC_RIGHT;
	}
	return -1;
}

void eval_run_config_defaults(eval_run_config_t *cfg)
{
	memset(cfg, 0, sizeof(*cfg));
	cfg->bf.delay_samples[EVAL_MIC_LEFT] = CONFIG_EVAL_BF_LEFT_DELAY;
	cfg->bf.delay_samples[EVAL_MIC_CENTER] = CONFIG_EVAL_BF_CENTER_DELAY;
	cfg->bf.delay_samples[EVAL_MIC_RIGHT] = CONFIG_EVAL_BF_RIGHT_DELAY;
	for (int i = 0; i < (int)EVAL_MIC_COUNT; i++) {
		cfg->bf.gain_q15[i] = CONFIG_EVAL_BF_GAIN_Q15;
		cfg->stream_raw[i] = true;
	}
	cfg->bf.out_gain_q15 = 32767;
	cfg->stream_bf = true;
	cfg->duration_s = CONFIG_EVAL_DEFAULT_DURATION_S;
	strcpy(cfg->label, "untitled");
	strcpy(cfg->clip, "");
	strcpy(cfg->environment, "quiet");
}
```

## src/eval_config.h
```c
/*
 * Central configuration for the 3-microphone beamforming evaluation.
 *
 * Pure C, no Zephyr dependency, so the DSP can be compiled on the host too.
 */
#ifndef EVAL_CONFIG_H_
#define EVAL_CONFIG_H_

#include <stdbool.h>
#include <stddef.h>
#include <stdint.h>

#ifdef __cplusplus
extern "C" {
#endif

#define EVAL_SAMPLE_RATE_HZ   16000U
#define EVAL_FRAME_SAMPLES    256U            /* one capture block, 16 ms */
#define EVAL_FRAME_MS         ((EVAL_FRAME_SAMPLES * 1000U) / EVAL_SAMPLE_RATE_HZ)
#define EVAL_MIC_COUNT        3U

#ifndef EVAL_MAX_DELAY_SAMPLES
#ifdef CONFIG_EVAL_MAX_DELAY_SAMPLES
#define EVAL_MAX_DELAY_SAMPLES CONFIG_EVAL_MAX_DELAY_SAMPLES
#else
#define EVAL_MAX_DELAY_SAMPLES 64
#endif
#endif

/* Physical microphones, in TDM slot order (left -> center -> right chain). */
typedef enum {
	EVAL_MIC_LEFT = 0,
	EVAL_MIC_CENTER = 1,
	EVAL_MIC_RIGHT = 2,
} eval_mic_t;

/*
 * Packet stream ids. Raw microphones use their eval_mic_t value; the on-device
 * beamformer output is EVAL_STREAM_BF. The host mirrors these in
 * tools/serial_protocol.py.
 */
typedef enum {
	EVAL_STREAM_RAW_LEFT = 0,
	EVAL_STREAM_RAW_CENTER = 1,
	EVAL_STREAM_RAW_RIGHT = 2,
	EVAL_STREAM_BF = 16,
	EVAL_STREAM_COUNT_ALL = 4,
	EVAL_STREAM_NONE = 0xFFFF,
} eval_stream_id_t;

typedef struct {
	int16_t delay_samples[EVAL_MIC_COUNT];   /* left, center, right            */
	int16_t gain_q15[EVAL_MIC_COUNT];        /* per-mic weight, 32767 = 1.0    */
	int16_t out_gain_q15;                    /* applied after the sum          */
} eval_bf_config_t;

typedef struct {
	eval_bf_config_t bf;
	bool stream_raw[EVAL_MIC_COUNT];
	bool stream_bf;
	uint16_t duration_s;          /* 0 = until stop */
	int16_t angle_deg;
	uint16_t distance_cm;
	char label[48];
	char clip[48];
	char environment[32];
} eval_run_config_t;

const char *eval_mic_name(eval_mic_t m);
const char *eval_stream_name(uint16_t stream_id);
int eval_mic_from_name(const char *name);        /* -1 if unknown */

void eval_run_config_defaults(eval_run_config_t *cfg);

#ifdef __cplusplus
}
#endif

#endif /* EVAL_CONFIG_H_ */
```

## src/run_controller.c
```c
#include <errno.h>
#include <stdio.h>
#include <string.h>

#include <zephyr/kernel.h>
#include <zephyr/logging/log.h>
#include <zephyr/sys/atomic.h>
#include <dk_buttons_and_leds.h>

#include "audio_capture_adapter.h"
#include "beamformer_delay_sum.h"
#include "run_controller.h"
#include "telemetry_transport.h"

LOG_MODULE_REGISTER(run, LOG_LEVEL_INF);

#ifndef CONFIG_EVAL_STATUS_PERIOD_MS
#define CONFIG_EVAL_STATUS_PERIOD_MS 1000
#endif

#define FW_VERSION "16_3mic_eval-1.0"

/* One second of frames at 16 ms each. */
#define STATS_FRAMES ((CONFIG_EVAL_STATUS_PERIOD_MS + EVAL_FRAME_MS - 1) / EVAL_FRAME_MS)

struct stream_stats {
	uint64_t energy;
	uint32_t samples;
	int32_t peak;
	uint32_t clips;
};

enum control_request {
	REQ_NONE = 0,
	REQ_START,
	REQ_STOP,
};

static eval_run_config_t config;
static struct bf_delay_sum beamformer;

static atomic_t state = ATOMIC_INIT(RUN_IDLE);
static atomic_t request = ATOMIC_INIT(REQ_NONE);
static char stop_reason[24] = "stop";

static uint16_t run_id;
static uint32_t run_start_seq;        /* capture seq of the first frame in the run  */
static uint32_t run_frames;           /* frames processed in this run               */
static uint32_t run_frames_expected;  /* from the run's seq span, includes drops    */
static uint32_t run_target_frames;    /* 0 = until stop                             */
static uint32_t frames_since_stats;
static struct stream_stats stats[EVAL_STREAM_COUNT_ALL];
static struct stream_stats levels[EVAL_MIC_COUNT];
static uint32_t levels_frames;

/* levels: 0 off, 1 once, 2 continuous */
static atomic_t levels_mode = ATOMIC_INIT(0);

K_THREAD_STACK_DEFINE(eval_stack, 8192);
static struct k_thread eval_thread_data;

static inline uint16_t stream_slot(uint16_t stream_id)
{
	return stream_id == EVAL_STREAM_BF ? 3U : stream_id;
}

static void stats_reset(struct stream_stats *s, size_t n)
{
	memset(s, 0, n * sizeof(*s));
}

static void stats_add(struct stream_stats *s, const int16_t *pcm, size_t count)
{
	for (size_t i = 0; i < count; i++) {
		int32_t v = pcm[i];
		int32_t a = v < 0 ? -v : v;

		s->energy += (uint64_t)((int64_t)v * v);
		if (a > s->peak) {
			s->peak = a;
		}
		if (v == INT16_MAX || v == INT16_MIN) {
			s->clips++;
		}
	}
	s->samples += (uint32_t)count;
}

static uint32_t isqrt64(uint64_t x)
{
	uint64_t op = x, res = 0, one = 1ULL << 62;

	while (one > op) {
		one >>= 2;
	}
	while (one != 0U) {
		if (op >= res + one) {
			op -= res + one;
			res = (res >> 1) + one;
		} else {
			res >>= 1;
		}
		one >>= 2;
	}
	return (uint32_t)res;
}

static uint32_t stats_rms(const struct stream_stats *s)
{
	return s->samples ? isqrt64(s->energy / s->samples) : 0U;
}

static void emit_audio_stats(uint32_t sample_index)
{
	tt_send_json(TP_AUDIO_STATS, run_id, (uint16_t)EVAL_STREAM_NONE, 0, sample_index, 0,
		     "{\"left\":[%u,%d,%u],\"center\":[%u,%d,%u],\"right\":[%u,%d,%u],"
		     "\"bf\":[%u,%d,%u],\"tx_ring\":%u}",
		     stats_rms(&stats[0]), stats[0].peak, stats[0].clips,
		     stats_rms(&stats[1]), stats[1].peak, stats[1].clips,
		     stats_rms(&stats[2]), stats[2].peak, stats[2].clips,
		     stats_rms(&stats[3]), stats[3].peak, stats[3].clips,
		     tt_ring_used());
	stats_reset(stats, EVAL_STREAM_COUNT_ALL);
}

static void emit_run_start(void)
{
	tt_send_json(TP_RUN_START, run_id, (uint16_t)EVAL_STREAM_NONE, 0, 0, 0,
		     "{\"run_id\":%u,\"label\":\"%s\",\"angle_deg\":%d,\"distance_cm\":%u,"
		     "\"environment\":\"%s\",\"clip\":\"%s\",\"duration_s\":%u,"
		     "\"sample_rate\":%u,\"frame\":%u,\"channels\":%u,\"tdm_slots\":%u,"
		     "\"streams\":{\"left\":%d,\"center\":%d,\"right\":%d,\"bf\":%d},"
		     "\"bf\":{\"delay\":[%d,%d,%d],\"gain\":[%d,%d,%d],\"out_gain\":%d},"
		     "\"fw\":\"%s\"}",
		     run_id, config.label, config.angle_deg, config.distance_cm,
		     config.environment, config.clip, config.duration_s,
		     (unsigned)EVAL_SAMPLE_RATE_HZ, (unsigned)EVAL_FRAME_SAMPLES,
		     (unsigned)EVAL_MIC_COUNT, audio_capture_tdm_slots(),
		     config.stream_raw[0], config.stream_raw[1], config.stream_raw[2],
		     config.stream_bf,
		     config.bf.delay_samples[0], config.bf.delay_samples[1],
		     config.bf.delay_samples[2], config.bf.gain_q15[0], config.bf.gain_q15[1],
		     config.bf.gain_q15[2], config.bf.out_gain_q15, FW_VERSION);
}

static void emit_run_end(const char *reason)
{
	struct audio_capture_stats cs;
	struct tt_stats ts;

	audio_capture_get_stats(&cs);
	tt_get_stats(&ts);

	uint32_t lost = run_frames_expected > run_frames ? run_frames_expected - run_frames : 0U;

	tt_send_json(TP_RUN_END, run_id, (uint16_t)EVAL_STREAM_NONE, 0, run_frames * EVAL_FRAME_SAMPLES,
		     TP_FLAG_FINAL,
		     "{\"run_id\":%u,\"reason\":\"%s\",\"frames\":%u,\"frames_expected\":%u,"
		     "\"frames_lost\":%u,\"duration_ms\":%u,\"capture_dropped\":%u,"
		     "\"i2s_errors\":%u,\"tx_dropped\":%u,\"tx_audio_dropped\":%u,"
		     "\"tx_high_water\":%u,\"tx_ring\":%u,\"bf_clips\":%u,\"unpack_us_max\":%u}",
		     run_id, reason, run_frames, run_frames_expected, lost,
		     (unsigned)(run_frames * EVAL_FRAME_MS), cs.frames_dropped, cs.i2s_errors,
		     ts.packets_dropped, ts.audio_dropped, ts.ring_high_water, ts.ring_size,
		     beamformer.clips, cs.unpack_us_max);

	if (!tt_binary_mode()) {
		tt_send_text(TP_TEXT, "RESULT  run %u (%s) at %d deg / %u cm / %s: %u frames (%u.%03u s), "
			     "%u lost, %u capture drops, %u link drops  %s",
			     run_id, config.label, config.angle_deg, config.distance_cm,
			     config.environment, run_frames, run_frames * EVAL_FRAME_MS / 1000U,
			     run_frames * EVAL_FRAME_MS % 1000U, lost, cs.frames_dropped,
			     ts.audio_dropped,
			     (lost == 0 && ts.audio_dropped == 0) ? "(VALID)" : "(DEGRADED)");
	}
}

static void begin_run(uint32_t first_seq)
{
	run_id++;
	run_start_seq = first_seq;
	run_frames = 0;
	run_frames_expected = 0;
	run_target_frames = config.duration_s
				    ? (uint32_t)config.duration_s * 1000U / EVAL_FRAME_MS
				    : 0U;
	frames_since_stats = 0;
	stats_reset(stats, EVAL_STREAM_COUNT_ALL);
	audio_capture_reset_stats();
	tt_reset_stats();
	bf_init(&beamformer, &config.bf);
	bf_reset(&beamformer);
	atomic_set(&state, RUN_RUNNING);
	dk_set_led_on(DK_LED1);
	emit_run_start();
	LOG_INF("run %u started: %s, %d deg, %u cm, %u s", run_id, config.label, config.angle_deg,
		config.distance_cm, config.duration_s);
}

static void end_run(const char *reason)
{
	emit_audio_stats(run_frames * EVAL_FRAME_SAMPLES);
	emit_run_end(reason);
	atomic_set(&state, RUN_IDLE);
	dk_set_led_off(DK_LED1);
	LOG_INF("run %u ended (%s): %u frames", run_id, reason, run_frames);
}

static void process_frame(const struct capture_frame *f)
{
	int16_t bf_out[EVAL_FRAME_SAMPLES];
	const int16_t *const mic[EVAL_MIC_COUNT] = { f->mic[0], f->mic[1], f->mic[2] };

	/*
	 * Sample index is derived from the capture seq, not from frames seen,
	 * so a dropped frame leaves a hole the host can detect and fill.
	 */
	uint32_t sample_index = (f->seq - run_start_seq) * EVAL_FRAME_SAMPLES;

	run_frames_expected = f->seq - run_start_seq + 1U;

	bf_process(&beamformer, mic, bf_out, f->count);

	for (int m = 0; m < (int)EVAL_MIC_COUNT; m++) {
		stats_add(&stats[m], f->mic[m], f->count);
		if (config.stream_raw[m]) {
			tt_send_audio(run_id, (uint16_t)m, f->seq - run_start_seq, sample_index, 0,
				      f->mic[m], f->count);
		}
	}
	stats_add(&stats[3], bf_out, f->count);
	if (config.stream_bf) {
		tt_send_audio(run_id, (uint16_t)EVAL_STREAM_BF, f->seq - run_start_seq, sample_index,
			      0, bf_out, f->count);
	}

	run_frames++;
	if (++frames_since_stats >= STATS_FRAMES) {
		frames_since_stats = 0;
		emit_audio_stats(sample_index + f->count);
	}
}

static void process_levels(const struct capture_frame *f)
{
	int mode = (int)atomic_get(&levels_mode);

	if (mode == 0) {
		return;
	}
	for (int m = 0; m < (int)EVAL_MIC_COUNT; m++) {
		stats_add(&levels[m], f->mic[m], f->count);
	}
	if (++levels_frames < STATS_FRAMES) {
		return;
	}
	tt_send_text(TP_TEXT, "levels  left[rms %u peak %d clips %u]  center[rms %u peak %d clips %u]  "
		     "right[rms %u peak %d clips %u]",
		     stats_rms(&levels[0]), levels[0].peak, levels[0].clips,
		     stats_rms(&levels[1]), levels[1].peak, levels[1].clips,
		     stats_rms(&levels[2]), levels[2].peak, levels[2].clips);
	stats_reset(levels, EVAL_MIC_COUNT);
	levels_frames = 0;
	if (mode == 1) {
		atomic_set(&levels_mode, 0);
	}
}

static void eval_thread(void *a, void *b, void *c)
{
	ARG_UNUSED(a);
	ARG_UNUSED(b);
	ARG_UNUSED(c);

	static struct capture_frame frame;
	struct k_msgq *q = audio_capture_queue();

	for (;;) {
		if (k_msgq_get(q, &frame, K_FOREVER) != 0) {
			continue;
		}

		enum control_request req = (enum control_request)atomic_set(&request, REQ_NONE);
		bool running = atomic_get(&state) == RUN_RUNNING;

		if (req == REQ_START && !running) {
			begin_run(frame.seq);
			running = true;
		} else if (req == REQ_STOP && running) {
			end_run(stop_reason);
			running = false;
		}

		if (running) {
			process_frame(&frame);
			if (run_target_frames && run_frames >= run_target_frames) {
				end_run("duration");
			}
		} else {
			process_levels(&frame);
		}
	}
}

/* ----------------------------------------------------------- public */

int run_controller_init(void)
{
	eval_run_config_defaults(&config);
	bf_init(&beamformer, &config.bf);

	k_thread_create(&eval_thread_data, eval_stack, K_THREAD_STACK_SIZEOF(eval_stack),
			eval_thread, NULL, NULL, NULL, 7, 0, K_NO_WAIT);
	k_thread_name_set(&eval_thread_data, "eval");
	return 0;
}

eval_run_config_t *run_controller_config(void)
{
	return &config;
}

bool run_controller_config_mutable(void)
{
	return atomic_get(&state) == RUN_IDLE && atomic_get(&request) == REQ_NONE;
}

enum run_state run_controller_state(void)
{
	return (enum run_state)atomic_get(&state);
}

uint16_t run_controller_run_id(void)
{
	return run_id;
}

int run_controller_start(char *err, size_t err_len)
{
	if (atomic_get(&state) != RUN_IDLE) {
		snprintf(err, err_len, "stop the run first");
		return -EBUSY;
	}
	if (!config.stream_raw[0] && !config.stream_raw[1] && !config.stream_raw[2] &&
	    !config.stream_bf) {
		snprintf(err, err_len, "no stream enabled (set_stream <left|center|right|bf> on)");
		return -EINVAL;
	}
	atomic_set(&request, REQ_START);
	return 0;
}

int run_controller_stop(const char *reason)
{
	if (atomic_get(&state) != RUN_RUNNING) {
		return -EALREADY;
	}
	strncpy(stop_reason, reason, sizeof(stop_reason) - 1);
	stop_reason[sizeof(stop_reason) - 1] = '\0';
	atomic_set(&request, REQ_STOP);
	return 0;
}

void run_controller_reset(void)
{
	eval_run_config_defaults(&config);
}

void run_controller_tick(void)
{
	/* LED2 shows that a host has the USB port open. */
	dk_set_led(DK_LED2, tt_host_connected() ? 1 : 0);
}

void run_controller_emit_hello(void)
{
	tt_send_json(TP_HELLO, 0, (uint16_t)EVAL_STREAM_NONE, 0, k_uptime_get_32(), 0,
		     "{\"device\":\"nrf54lm20dk\",\"fw\":\"%s\",\"protocol\":%u,\"sample_rate\":%u,"
		     "\"frame\":%u,\"channels\":%u,\"tdm_slots\":%u,"
		     "\"streams\":[\"raw_left\",\"raw_center\",\"raw_right\",\"bf\"],"
		     "\"stream_ids\":[0,1,2,16],\"binary\":%d}",
		     FW_VERSION, (unsigned)TP_VERSION, (unsigned)EVAL_SAMPLE_RATE_HZ,
		     (unsigned)EVAL_FRAME_SAMPLES, (unsigned)EVAL_MIC_COUNT,
		     audio_capture_tdm_slots(), tt_binary_mode());
}

void run_controller_emit_status(void)
{
	struct audio_capture_stats cs;
	struct tt_stats ts;

	audio_capture_get_stats(&cs);
	tt_get_stats(&ts);
	tt_send_json(TP_STATUS, run_id, (uint16_t)EVAL_STREAM_NONE, 0, k_uptime_get_32(), 0,
		     "{\"state\":\"%s\",\"run_id\":%u,\"frames\":%u,\"captured\":%u,"
		     "\"capture_dropped\":%u,\"queue_hw\":%u,\"i2s_errors\":%u,\"tx_dropped\":%u,"
		     "\"tx_high_water\":%u,\"tx_ring\":%u,\"rx_bad_crc\":%u,\"host\":%d}",
		     atomic_get(&state) == RUN_RUNNING ? "running" : "idle", run_id, run_frames,
		     cs.frames_captured, cs.frames_dropped, cs.queue_high_water, cs.i2s_errors,
		     ts.packets_dropped, ts.ring_high_water, ts.ring_size, ts.rx_bad_crc,
		     tt_host_connected());
}

void run_controller_emit_config(void)
{
	tt_send_json(TP_RUN_CONFIG, run_id, (uint16_t)EVAL_STREAM_NONE, 0, k_uptime_get_32(), 0,
		     "{\"label\":\"%s\",\"angle_deg\":%d,\"distance_cm\":%u,\"environment\":\"%s\","
		     "\"clip\":\"%s\",\"duration_s\":%u,"
		     "\"streams\":{\"left\":%d,\"center\":%d,\"right\":%d,\"bf\":%d},"
		     "\"bf\":{\"delay\":[%d,%d,%d],\"gain\":[%d,%d,%d],\"out_gain\":%d}}",
		     config.label, config.angle_deg, config.distance_cm, config.environment,
		     config.clip, config.duration_s, config.stream_raw[0], config.stream_raw[1],
		     config.stream_raw[2], config.stream_bf, config.bf.delay_samples[0],
		     config.bf.delay_samples[1], config.bf.delay_samples[2], config.bf.gain_q15[0],
		     config.bf.gain_q15[1], config.bf.gain_q15[2], config.bf.out_gain_q15);
}

void run_controller_request_levels(bool continuous, bool off)
{
	stats_reset(levels, EVAL_MIC_COUNT);
	levels_frames = 0;
	atomic_set(&levels_mode, off ? 0 : (continuous ? 2 : 1));
}
```

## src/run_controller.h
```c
/*
 * Run controller: owns the run configuration and the evaluation thread that
 * turns queued microphone frames into the on-device beamformer output,
 * per-stream level statistics and the audio streams sent to the host.
 *
 * A "run" is one recording: it starts on BTN1 or `start`, streams the raw
 * microphones (and the beamformer output) continuously, and ends after the
 * configured duration, on BTN2 or on `stop`. Everything that touches the run
 * state happens on the evaluation thread, ordered with the audio frames.
 */
#ifndef RUN_CONTROLLER_H_
#define RUN_CONTROLLER_H_

#include <stdbool.h>
#include <stddef.h>
#include <stdint.h>

#include "eval_config.h"

enum run_state {
	RUN_IDLE = 0,
	RUN_RUNNING,
};

int run_controller_init(void);

/* Configuration is only writable while idle. */
eval_run_config_t *run_controller_config(void);
bool run_controller_config_mutable(void);

enum run_state run_controller_state(void);
uint16_t run_controller_run_id(void);

/* Requests a start. Fails with -EBUSY if a run is active. */
int run_controller_start(char *err, size_t err_len);
int run_controller_stop(const char *reason);
void run_controller_reset(void);

/* 10 ms housekeeping from main: LEDs, idle status. */
void run_controller_tick(void);

void run_controller_emit_hello(void);
void run_controller_emit_status(void);
void run_controller_emit_config(void);

/* Text mode: print the raw microphones' level once, every second, or stop. */
void run_controller_request_levels(bool continuous, bool off);

#endif /* RUN_CONTROLLER_H_ */
```

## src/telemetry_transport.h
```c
/*
 * Telemetry transport over the DK's USB high-speed port (CDC ACM).
 *
 * Device -> host: a lock-protected transmit ring, drained by the CDC ACM
 * class's interrupt-driven UART API whenever the host has room. Audio capture
 * never waits on the link; when the ring is full a packet is dropped and
 * counted, and the host sees the hole in the audio sample index.
 *
 * Host -> device: bytes are read in the UART callback into a byte ring and
 * parsed by a small thread. Framed packets and plain text lines are both
 * accepted, so a terminal can drive the device without any tooling.
 *
 * Text vs binary mode: the device boots in text mode and prints readable
 * lines. The host tool sends "binary_mode on" and every outgoing message is
 * then framed (TP_TEXT for human lines, TP_AUDIO_CHUNK for audio).
 *
 * Zephyr logging stays on uart20 (the J-Link virtual COM port), separate
 * from this link, so log text can never tear a binary packet apart and the
 * debug console keeps working even when the USB cable is unplugged.
 */
#ifndef TELEMETRY_TRANSPORT_H_
#define TELEMETRY_TRANSPORT_H_

#include <stdbool.h>
#include <stddef.h>
#include <stdint.h>

#include "telemetry_protocol.h"

struct tt_stats {
	uint32_t bytes_sent;
	uint32_t packets_sent;
	uint32_t packets_dropped;    /* ring full */
	uint32_t audio_dropped;      /* subset of packets_dropped that were audio */
	uint32_t ring_high_water;
	uint32_t ring_size;
	uint32_t rx_bytes;
	uint32_t rx_packets;
	uint32_t rx_bad_crc;
	uint32_t rx_resyncs;
	uint32_t rx_overflow;
};

typedef void (*tt_rx_line_cb_t)(const char *line);
typedef void (*tt_rx_packet_cb_t)(const struct tp_header *h, const uint8_t *payload);

int tt_init(void);
void tt_set_rx_callbacks(tt_rx_line_cb_t line_cb, tt_rx_packet_cb_t packet_cb);

void tt_set_binary_mode(bool on);
bool tt_binary_mode(void);

/* True while a host has the CDC ACM port open (DTR asserted). */
bool tt_host_connected(void);

/* Framed send. Returns 0, or -ENOSPC if the ring cannot take the whole packet. */
int tt_send(const struct tp_header *h, const void *payload, size_t len);

/* Text-type packet (TP_LOG, TP_ACK, TP_TEXT, TP_ERROR). In text mode the
 * line is written raw. printf-style; the line must fit in 240 bytes. */
int tt_send_text(uint8_t type, const char *fmt, ...);

/* JSON-type packet. printf-style; payload must fit in 960 bytes. In text mode
 * the payload is written as "<TYPE> {json}". */
int tt_send_json(uint8_t type, uint16_t run_id, uint16_t stream_id, uint32_t seq,
		 uint32_t timestamp, uint16_t flags, const char *fmt, ...);

/* Audio chunk. Silently discarded in text mode. */
int tt_send_audio(uint16_t run_id, uint16_t stream_id, uint32_t seq, uint32_t sample_index,
		  uint16_t flags, const int16_t *pcm, size_t samples);

void tt_get_stats(struct tt_stats *out);
void tt_reset_stats(void);

/* Bytes currently queued, for queue-watermark telemetry. */
uint32_t tt_ring_used(void);

#endif /* TELEMETRY_TRANSPORT_H_ */
```
